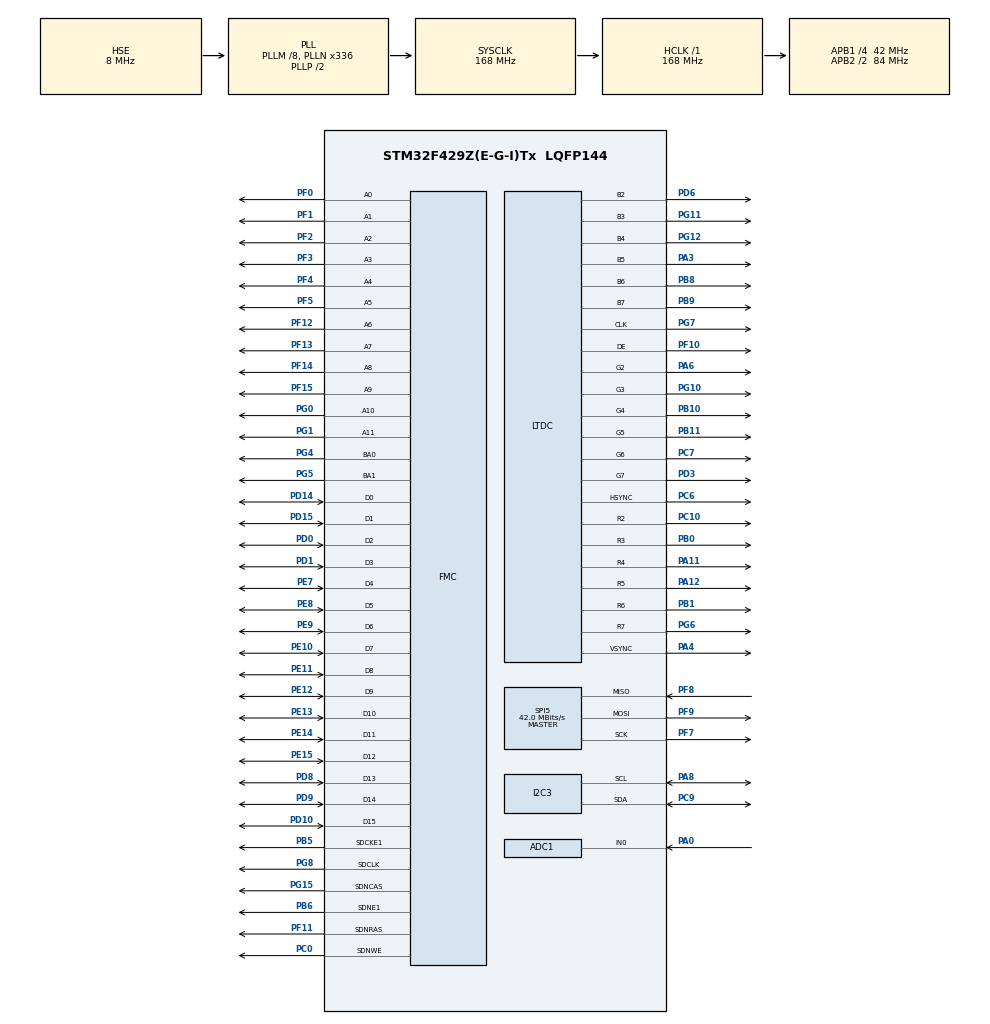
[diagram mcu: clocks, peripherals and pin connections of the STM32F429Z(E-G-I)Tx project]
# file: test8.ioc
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ADC1.Channel-0\#ChannelRegularConversion=ADC_CHANNEL_0
ADC1.Channel-1\#ChannelInjectedConversion=ADC_CHANNEL_0
ADC1.ContinuousConvMode=ENABLE
ADC1.InjNumberOfConversion=1
ADC1.InjectedOffset-1\#ChannelInjectedConversion=0
ADC1.NbrOfConversionFlag=1
ADC1.Rank-0\#ChannelRegularConversion=1
ADC1.Rank-1\#ChannelInjectedConversion=1
ADC1.SamplingTime-0\#ChannelRegularConversion=ADC_SAMPLETIME_3CYCLES
ADC1.SamplingTime-1\#ChannelInjectedConversion=ADC_SAMPLETIME_3CYCLES
ADC1.ScanConvMode=ENABLE
ADC1.master=1
DMA2D.ColorMode=DMA2D_RGB565
LTDC.ActiveH=240
LTDC.ActiveW=320
Mcu.Family=STM32F4
Mcu.Name=STM32F429Z(E-G-I)Tx
Mcu.Package=LQFP144
NVIC.PriorityGroup=NVIC_PRIORITYGROUP_4
PA0/WKUP.Signal=ADCx_IN0
PA11.Mode=RGB666
PA11.Signal=LTDC_R4
PA12.Mode=RGB666
PA12.Signal=LTDC_R5
PA3.Mode=RGB666
PA3.Signal=LTDC_B5
PA4.Mode=RGB666
PA4.Signal=LTDC_VSYNC
PA6.Mode=RGB666
PA6.Signal=LTDC_G2
PA8.Mode=I2C
PA8.Signal=I2C3_SCL
PB0.Mode=RGB666
PB0.Signal=LTDC_R3
PB1.Mode=RGB666
PB1.Signal=LTDC_R6
PB10.Mode=RGB666
PB10.Signal=LTDC_G4
PB11.Mode=RGB666
PB11.Signal=LTDC_G5
PB5.Mode=SdramChipSelect2_1
PB5.Signal=FMC_SDCKE1
PB6.Mode=SdramChipSelect2_1
PB6.Signal=FMC_SDNE1
PB8.Mode=RGB666
PB8.Signal=LTDC_B6
PB9.Mode=RGB666
PB9.Signal=LTDC_B7
PC0.Signal=FMC_SDNWE
PC10.Mode=RGB666
PC10.Signal=LTDC_R2
PC6.Mode=RGB666
PC6.Signal=LTDC_HSYNC
PC7.Mode=RGB666
PC7.Signal=LTDC_G6
PC9.Mode=I2C
PC9.Signal=I2C3_SDA
PD0.Signal=FMC_D2_DA2
PD1.Signal=FMC_D3_DA3
PD10.Signal=FMC_D15_DA15
PD14.Signal=FMC_D0_DA0
PD15.Signal=FMC_D1_DA1
PD3.Mode=RGB666
PD3.Signal=LTDC_G7
PD6.Mode=RGB666
PD6.Signal=LTDC_B2
PD8.Signal=FMC_D13_DA13
PD9.Signal=FMC_D14_DA14
PE10.Signal=FMC_D7_DA7
PE11.Signal=FMC_D8_DA8
PE12.Signal=FMC_D9_DA9
PE13.Signal=FMC_D10_DA10
PE14.Signal=FMC_D11_DA11
PE15.Signal=FMC_D12_DA12
PE7.Signal=FMC_D4_DA4
PE8.Signal=FMC_D5_DA5
PE9.Signal=FMC_D6_DA6
PF0.Signal=FMC_A0
PF1.Signal=FMC_A1
PF10.Mode=RGB666
PF10.Signal=LTDC_DE
PF11.Signal=FMC_SDNRAS
PF12.Signal=FMC_A6
PF13.Signal=FMC_A7
PF14.Signal=FMC_A8
PF15.Signal=FMC_A9
PF2.Signal=FMC_A2
PF3.Signal=FMC_A3
PF4.Signal=FMC_A4
PF5.Signal=FMC_A5
PF7.Mode=Full_Duplex_Master
PF7.Signal=SPI5_SCK
PF8.Mode=Full_Duplex_Master
PF8.Signal=SPI5_MISO
PF9.Mode=Full_Duplex_Master
PF9.Signal=SPI5_MOSI
PG0.Signal=FMC_A10
PG1.Signal=FMC_A11
PG10.Mode=RGB666
PG10.Signal=LTDC_G3
PG11.Mode=RGB666
PG11.Signal=LTDC_B3
PG12.Mode=RGB666
PG12.Signal=LTDC_B4
PG15.Signal=FMC_SDNCAS
PG4.Signal=FMC_A14_BA0
PG5.Signal=FMC_A15_BA1
PG6.Mode=RGB666
PG6.Signal=LTDC_R7
PG7.Mode=RGB666
PG7.Signal=LTDC_CLK
PG8.Signal=FMC_SDCLK
PH0/OSC_IN.Mode=HSE-External-Oscillator
PH0/OSC_IN.Signal=RCC_OSC_IN
PH1/OSC_OUT.Mode=HSE-External-Oscillator
PH1/OSC_OUT.Signal=RCC_OSC_OUT
ProjectManager.TargetToolchain=MDK-ARM V5
RCC.48MHZClocksFreq_Value=42000000
RCC.AHBFreq_Value=168000000
RCC.APB1CLKDivider=RCC_HCLK_DIV4
RCC.APB1Freq_Value=42000000
RCC.APB1TimFreq_Value=84000000
RCC.APB2CLKDivider=RCC_HCLK_DIV2
RCC.APB2Freq_Value=84000000
RCC.APB2TimFreq_Value=168000000
RCC.CortexFreq_Value=168000000
RCC.HCLKFreq_Value=168000000
RCC.HSE_VALUE=8000000
RCC.HSI_VALUE=16000000
RCC.LSE_VALUE=32768
RCC.PLLM=8
RCC.PLLN=336
RCC.PLLQ=8
RCC.PLLSAIN=432
RCC.PLLSourceVirtual=RCC_PLLSOURCE_HSE
RCC.SYSCLKFreq_VALUE=168000000
RCC.SYSCLKSource=RCC_SYSCLKSOURCE_PLLCLK
RCC.VCOOutputFreq_Value=336000000
SH.ADCx_IN0.0=ADC1_IN0,IN0
SH.FMC_A0.0=FMC_A0,12b-sda1
SH.FMC_A1.0=FMC_A1,12b-sda1
SH.FMC_A10.0=FMC_A10,12b-sda1
SH.FMC_A11.0=FMC_A11,12b-sda1
SH.FMC_A14_BA0.0=FMC_BA0,FourSdramBanks1
SH.FMC_A15_BA1.0=FMC_BA1,FourSdramBanks1
SH.FMC_A2.0=FMC_A2,12b-sda1
SH.FMC_A3.0=FMC_A3,12b-sda1
SH.FMC_A4.0=FMC_A4,12b-sda1
SH.FMC_A5.0=FMC_A5,12b-sda1
SH.FMC_A6.0=FMC_A6,12b-sda1
SH.FMC_A7.0=FMC_A7,12b-sda1
SH.FMC_A8.0=FMC_A8,12b-sda1
SH.FMC_A9.0=FMC_A9,12b-sda1
SH.FMC_D0_DA0.0=FMC_D0,sd-16b-d1
SH.FMC_D10_DA10.0=FMC_D10,sd-16b-d1
SH.FMC_D11_DA11.0=FMC_D11,sd-16b-d1
SH.FMC_D12_DA12.0=FMC_D12,sd-16b-d1
SH.FMC_D13_DA13.0=FMC_D13,sd-16b-d1
SH.FMC_D14_DA14.0=FMC_D14,sd-16b-d1
SH.FMC_D15_DA15.0=FMC_D15,sd-16b-d1
SH.FMC_D1_DA1.0=FMC_D1,sd-16b-d1
SH.FMC_D2_DA2.0=FMC_D2,sd-16b-d1
SH.FMC_D3_DA3.0=FMC_D3,sd-16b-d1
SH.FMC_D4_DA4.0=FMC_D4,sd-16b-d1
SH.FMC_D5_DA5.0=FMC_D5,sd-16b-d1
SH.FMC_D6_DA6.0=FMC_D6,sd-16b-d1
SH.FMC_D7_DA7.0=FMC_D7,sd-16b-d1
SH.FMC_D8_DA8.0=FMC_D8,sd-16b-d1
SH.FMC_D9_DA9.0=FMC_D9,sd-16b-d1
SH.FMC_SDCLK.0=FMC_SDCLK,12b-sda1
SH.FMC_SDNCAS.0=FMC_SDNCAS,12b-sda1
SH.FMC_SDNRAS.0=FMC_SDNRAS,12b-sda1
SH.FMC_SDNWE.0=FMC_SDNWE,12b-sda1
SPI5.CalculateBaudRate=42.0 MBits/s
SPI5.Mode=SPI_MODE_MASTER
VP_DMA2D_VS_DMA2D.Mode=DMA2D_Activate
VP_RNG_VS_RNG.Mode=RNG_Activate
board=test2

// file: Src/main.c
/**
  ******************************************************************************
  * File Name          : main.c
  * Description        : Main program body
  ******************************************************************************
  *
  * COPYRIGHT(c) 2015 STMicroelectronics
  *
  * Redistribution and use in source and binary forms, with or without modification,
  * are permitted provided that the following conditions are met:
  *   1. Redistributions of source code must retain the above copyright notice,
  *      this list of conditions and the following disclaimer.
  *   2. Redistributions in binary form must reproduce the above copyright notice,
  *      this list of conditions and the following disclaimer in the documentation
  *      and/or other materials provided with the distribution.
  *   3. Neither the name of STMicroelectronics nor the names of its contributors
  *      may be used to endorse or promote products derived from this software
  *      without specific prior written permission.
  *
  * THIS SOFTWARE IS PROVIDED BY THE COPYRIGHT HOLDERS AND CONTRIBUTORS "AS IS"
  * AND ANY EXPRESS OR IMPLIED WARRANTIES, INCLUDING, BUT NOT LIMITED TO, THE
  * IMPLIED WARRANTIES OF MERCHANTABILITY AND FITNESS FOR A PARTICULAR PURPOSE ARE
  * DISCLAIMED. IN NO EVENT SHALL THE COPYRIGHT HOLDER OR CONTRIBUTORS BE LIABLE
  * FOR ANY DIRECT, INDIRECT, INCIDENTAL, SPECIAL, EXEMPLARY, OR CONSEQUENTIAL
  * DAMAGES (INCLUDING, BUT NOT LIMITED TO, PROCUREMENT OF SUBSTITUTE GOODS OR
  * SERVICES; LOSS OF USE, DATA, OR PROFITS; OR BUSINESS INTERRUPTION) HOWEVER
  * CAUSED AND ON ANY THEORY OF LIABILITY, WHETHER IN CONTRACT, STRICT LIABILITY,
  * OR TORT (INCLUDING NEGLIGENCE OR OTHERWISE) ARISING IN ANY WAY OUT OF THE USE
  * OF THIS SOFTWARE, EVEN IF ADVISED OF THE POSSIBILITY OF SUCH DAMAGE.
  *
  ******************************************************************************
  */
#include "stm32f4xx_hal.h"
#include "stm32f4xx.h"
#include <stdio.h>
#include "stdint.h"
#include "arm_math.h"

/* USER CODE BEGIN Includes */
#include "stm32f429i_discovery_lcd.h"
/* USER CODE END Includes */

#define MAX_VALUE 4095.0
#define SIZE 2048
#define FREQ_FACTOR 58
#define CAP_FACTOR 5 //spadek napiecia na kondensatorze

ADC_HandleTypeDef hadc1;

DMA2D_HandleTypeDef hdma2d;

I2C_HandleTypeDef hi2c3;

LTDC_HandleTypeDef hltdc;

RNG_HandleTypeDef hrng;

SPI_HandleTypeDef hspi5;

SDRAM_HandleTypeDef hsdram1;

/* USER CODE BEGIN PV */
/* Private variables ---------------------------------------------------------*/

/* USER CODE END PV */

void SystemClock_Config(void);
static void MX_GPIO_Init(void);
static void MX_ADC1_Init(void);
static void MX_DMA2D_Init(void);
static void MX_FMC_Init(void);
static void MX_I2C3_Init(void);
static void MX_LTDC_Init(void);
static void MX_RNG_Init(void);
static void MX_SPI5_Init(void);

uint32_t samples[SIZE];

uint32_t scale(uint32_t value) {
	return value/MAX_VALUE*240;
}

uint32_t find_trigger_point(uint32_t *samples) {
	uint32_t middle = MAX_VALUE/2;

	for(int i = 2; i < SIZE; i += 2) {
		if(samples[i] > middle && samples[i-2] < middle) {
			return i;
		}
	}
	return -1;
}

void display_samples(uint32_t *samples) {
	uint32_t trigger_point = find_trigger_point(samples); //to synchronize
	BSP_LCD_Clear(LCD_COLOR_BLACK);
	for(uint32_t i = trigger_point+2; i < SIZE; i += 2) {
		BSP_LCD_DrawPixel(scale(samples[i]),i-trigger_point,LCD_COLOR_WHITE);
	}
}

float32_t INPUT[SIZE];
float32_t Output[SIZE];

void fft();

int main(void)
{

  HAL_Init();

  SystemClock_Config();

  MX_GPIO_Init();
  MX_ADC1_Init();
  MX_DMA2D_Init();
  MX_FMC_Init();
  MX_I2C3_Init();
  MX_LTDC_Init();
  MX_RNG_Init();
  MX_SPI5_Init();

	BSP_LCD_Init();
	BSP_LCD_LayerDefaultInit(LCD_BACKGROUND_LAYER, LCD_FRAME_BUFFER);
	BSP_LCD_LayerDefaultInit(LCD_FOREGROUND_LAYER, LCD_FRAME_BUFFER);
	BSP_LCD_SelectLayer(LCD_FOREGROUND_LAYER);
	BSP_LCD_Clear(LCD_COLOR_BLACK);
	BSP_LCD_DisplayOn();
	uint8_t Button_Value;
	GPIO_InitTypeDef GPIO_InitStruct;
  GPIO_InitStruct.Pin |= GPIO_PIN_0;
  GPIO_InitStruct.Mode = 0x00;
  GPIO_InitStruct.Pull = 0x02;
  HAL_GPIO_Init(GPIOA, &GPIO_InitStruct);
	while (1)
		{

		for(uint16_t i = 0; i < SIZE; i+=2) {
			HAL_ADC_Start(&hadc1);
			HAL_ADC_PollForConversion(&hadc1,1000);
			samples[i] = HAL_ADC_GetValue(&hadc1);
			samples[i+1] = 0;
			HAL_ADC_Stop(&hadc1);
		}

		Button_Value = HAL_GPIO_ReadPin(GPIOA, GPIO_PIN_0);
		if( Button_Value )
		{
			fft();

		}
		else
		{

			display_samples(samples);

		}
	}
}

/**FFT
*/

void fft(){
	uint32_t i;
	arm_cfft_radix4_instance_f32 S;	/* ARM CFFT module */
	float32_t maxValue;				/* Max FFT value is stored here */
	uint32_t maxIndex;				/* Index in Output array where max value is */
	uint32_t height;
	for(i = 0; i < SIZE; i+=2)
	{
		INPUT[i] = ((samples[i]+CAP_FACTOR)/((float32_t) MAX_VALUE/2) - 1);
		INPUT[i+1] = 0;
	}
			/* Initialize the CFFT/CIFFT module, intFlag = 0, doBitReverse = 1 */
		arm_cfft_radix4_init_f32(&S, SIZE/2, 0, 1);
		/* Process the data through the CFFT/CIFFT module */
		arm_cfft_radix4_f32(&S, INPUT);
		/* Process the data through the Complex Magniture Module for calculating the magnitude at each bin */
		arm_cmplx_mag_f32(INPUT, Output, SIZE/2);
		/* Calculates maxValue and returns corresponding value */
		arm_max_f32(Output, SIZE, &maxValue, &maxIndex);
		if(maxIndex>SIZE/4){
			maxIndex=SIZE/2-maxIndex;		//Dla lustrzanych
		}
		BSP_LCD_Clear(LCD_COLOR_WHITE);
		/* Display data on LCD */
		for (i = 0; i < SIZE; i++) {
			/* Draw FFT results */
				height = (uint16_t)(((float32_t)Output[i] / (float32_t)maxValue) * 180);
				BSP_LCD_DrawLine(0, 30+i, height, 30+i);

		}
		char str[16];
		sprintf(str,"%d",(uint32_t)((float32_t)maxIndex*FREQ_FACTOR)); //Model matematyczny
		BSP_LCD_DisplayStringAtLine(1,(uint8_t *) str);
}
/** System Clock Configuration
*/
void SystemClock_Config(void)
{

  RCC_OscInitTypeDef RCC_OscInitStruct;
  RCC_ClkInitTypeDef RCC_ClkInitStruct;
  RCC_PeriphCLKInitTypeDef PeriphClkInitStruct;

  __PWR_CLK_ENABLE();

  __HAL_PWR_VOLTAGESCALING_CONFIG(PWR_REGULATOR_VOLTAGE_SCALE1);

  RCC_OscInitStruct.OscillatorType = RCC_OSCILLATORTYPE_HSE;
  RCC_OscInitStruct.HSEState = RCC_HSE_ON;
  RCC_OscInitStruct.PLL.PLLState = RCC_PLL_ON;
  RCC_OscInitStruct.PLL.PLLSource = RCC_PLLSOURCE_HSE;
  RCC_OscInitStruct.PLL.PLLM = 8;
  RCC_OscInitStruct.PLL.PLLN = 336;
  RCC_OscInitStruct.PLL.PLLP = RCC_PLLP_DIV2;
  RCC_OscInitStruct.PLL.PLLQ = 8;
  HAL_RCC_OscConfig(&RCC_OscInitStruct);

  RCC_ClkInitStruct.ClockType = RCC_CLOCKTYPE_SYSCLK|RCC_CLOCKTYPE_PCLK1
                              |RCC_CLOCKTYPE_PCLK2;
  RCC_ClkInitStruct.SYSCLKSource = RCC_SYSCLKSOURCE_PLLCLK;
  RCC_ClkInitStruct.AHBCLKDivider = RCC_SYSCLK_DIV1;
  RCC_ClkInitStruct.APB1CLKDivider = RCC_HCLK_DIV4;
  RCC_ClkInitStruct.APB2CLKDivider = RCC_HCLK_DIV2;
  HAL_RCC_ClockConfig(&RCC_ClkInitStruct, FLASH_LATENCY_5);

  PeriphClkInitStruct.PeriphClockSelection = RCC_PERIPHCLK_LTDC;
  PeriphClkInitStruct.PLLSAI.PLLSAIN = 432;
  PeriphClkInitStruct.PLLSAI.PLLSAIR = 2;
  PeriphClkInitStruct.PLLSAIDivR = RCC_PLLSAIDIVR_2;
  HAL_RCCEx_PeriphCLKConfig(&PeriphClkInitStruct);

  HAL_SYSTICK_Config(HAL_RCC_GetHCLKFreq()/1000);

  HAL_SYSTICK_CLKSourceConfig(SYSTICK_CLKSOURCE_HCLK);

}

/* ADC1 init function */
void MX_ADC1_Init(void)
{

  ADC_ChannelConfTypeDef sConfig;
  ADC_InjectionConfTypeDef sConfigInjected;

    /**Configure the global features of the ADC (Clock, Resolution, Data Alignment and number of conversion)
    */
  hadc1.Instance = ADC1;
  hadc1.Init.ClockPrescaler = ADC_CLOCKPRESCALER_PCLK_DIV4;
  hadc1.Init.Resolution = ADC_RESOLUTION12b;
  hadc1.Init.ScanConvMode = ENABLE;
  hadc1.Init.ContinuousConvMode = ENABLE;
  hadc1.Init.DiscontinuousConvMode = DISABLE;
  hadc1.Init.ExternalTrigConvEdge = ADC_EXTERNALTRIGCONVEDGE_NONE;
  hadc1.Init.DataAlign = ADC_DATAALIGN_RIGHT;
  hadc1.Init.NbrOfConversion = 1;
  hadc1.Init.DMAContinuousRequests = DISABLE;
  hadc1.Init.EOCSelection = EOC_SINGLE_CONV;
  HAL_ADC_Init(&hadc1);

    /**Configure for the selected ADC regular channel its corresponding rank in the sequencer and its sample time.
    */
  sConfig.Channel = ADC_CHANNEL_5;
  sConfig.Rank = 1;
  sConfig.SamplingTime = ADC_SAMPLETIME_3CYCLES;
  HAL_ADC_ConfigChannel(&hadc1, &sConfig);

    /**Configures for the selected ADC injected channel its corresponding rank in the sequencer and its sample time
    */
  sConfigInjected.InjectedChannel = ADC_CHANNEL_5;
  sConfigInjected.InjectedRank = 1;
  sConfigInjected.InjectedNbrOfConversion = 1;
  sConfigInjected.InjectedSamplingTime = ADC_SAMPLETIME_3CYCLES;
  sConfigInjected.ExternalTrigInjecConvEdge = ADC_EXTERNALTRIGINJECCONVEDGE_NONE;
  sConfigInjected.AutoInjectedConv = DISABLE;
  sConfigInjected.InjectedDiscontinuousConvMode = DISABLE;
  sConfigInjected.InjectedOffset = 0;
  HAL_ADCEx_InjectedConfigChannel(&hadc1, &sConfigInjected);

}

/* DMA2D init function */
void MX_DMA2D_Init(void)
{

  hdma2d.Instance = DMA2D;
  hdma2d.Init.Mode = DMA2D_M2M;
  hdma2d.Init.ColorMode = DMA2D_RGB565;
  hdma2d.Init.OutputOffset = 0;
  hdma2d.LayerCfg[1].InputOffset = 0;
  hdma2d.LayerCfg[1].InputColorMode = CM_RGB565;
  hdma2d.LayerCfg[1].AlphaMode = DMA2D_NO_MODIF_ALPHA;
  hdma2d.LayerCfg[1].InputAlpha = 0;
  HAL_DMA2D_Init(&hdma2d);

  HAL_DMA2D_ConfigLayer(&hdma2d, 1);

}

/* I2C3 init function */
void MX_I2C3_Init(void)
{

  hi2c3.Instance = I2C3;
  hi2c3.Init.ClockSpeed = 100000;
  hi2c3.Init.DutyCycle = I2C_DUTYCYCLE_2;
  hi2c3.Init.OwnAddress1 = 0;
  hi2c3.Init.AddressingMode = I2C_ADDRESSINGMODE_7BIT;
  hi2c3.Init.DualAddressMode = I2C_DUALADDRESS_DISABLED;
  hi2c3.Init.OwnAddress2 = 0;
  hi2c3.Init.GeneralCallMode = I2C_GENERALCALL_DISABLED;
  hi2c3.Init.NoStretchMode = I2C_NOSTRETCH_DISABLED;
  HAL_I2C_Init(&hi2c3);

}

/* LTDC init function */
void MX_LTDC_Init(void)
{

  LTDC_LayerCfgTypeDef pLayerCfg;
  LTDC_LayerCfgTypeDef pLayerCfg1;

  hltdc.Instance = LTDC;
  hltdc.Init.HSPolarity = LTDC_HSPOLARITY_AL;
  hltdc.Init.VSPolarity = LTDC_VSPOLARITY_AL;
  hltdc.Init.DEPolarity = LTDC_DEPOLARITY_AL;
  hltdc.Init.PCPolarity = LTDC_PCPOLARITY_IPC;
  hltdc.Init.HorizontalSync = 7;
  hltdc.Init.VerticalSync = 3;
  hltdc.Init.AccumulatedHBP = 14;
  hltdc.Init.AccumulatedVBP = 5;
  hltdc.Init.AccumulatedActiveW = 334;
  hltdc.Init.AccumulatedActiveH = 245;
  hltdc.Init.TotalWidth = 340;
  hltdc.Init.TotalHeigh = 247;
  hltdc.Init.Backcolor.Blue = 0;
  hltdc.Init.Backcolor.Green = 0;
  hltdc.Init.Backcolor.Red = 0;
  HAL_LTDC_Init(&hltdc);

  pLayerCfg.WindowX0 = 0;
  pLayerCfg.WindowX1 = 0;
  pLayerCfg.WindowY0 = 0;
  pLayerCfg.WindowY1 = 0;
  pLayerCfg.PixelFormat = LTDC_PIXEL_FORMAT_ARGB8888;
  pLayerCfg.Alpha = 0;
  pLayerCfg.Alpha0 = 0;
  pLayerCfg.BlendingFactor1 = LTDC_BLENDING_FACTOR1_CA;
  pLayerCfg.BlendingFactor2 = LTDC_BLENDING_FACTOR2_CA;
  pLayerCfg.FBStartAdress = 0;
  pLayerCfg.ImageWidth = 0;
  pLayerCfg.ImageHeight = 0;
  pLayerCfg.Backcolor.Blue = 0;
  pLayerCfg.Backcolor.Green = 0;
  pLayerCfg.Backcolor.Red = 0;
  HAL_LTDC_ConfigLayer(&hltdc, &pLayerCfg, 0);

  pLayerCfg1.WindowX0 = 0;
  pLayerCfg1.WindowX1 = 0;
  pLayerCfg1.WindowY0 = 0;
  pLayerCfg1.WindowY1 = 0;
  pLayerCfg1.PixelFormat = LTDC_PIXEL_FORMAT_ARGB8888;
  pLayerCfg1.Alpha = 0;
  pLayerCfg1.Alpha0 = 0;
  pLayerCfg1.BlendingFactor1 = LTDC_BLENDING_FACTOR1_CA;
  pLayerCfg1.BlendingFactor2 = LTDC_BLENDING_FACTOR2_CA;
  pLayerCfg1.FBStartAdress = 0;
  pLayerCfg1.ImageWidth = 0;
  pLayerCfg1.ImageHeight = 0;
  pLayerCfg1.Backcolor.Blue = 0;
  pLayerCfg1.Backcolor.Green = 0;
  pLayerCfg1.Backcolor.Red = 0;
  HAL_LTDC_ConfigLayer(&hltdc, &pLayerCfg1, 1);

}

/* RNG init function */
void MX_RNG_Init(void)
{

  hrng.Instance = RNG;
  HAL_RNG_Init(&hrng);

}

/* SPI5 init function */
void MX_SPI5_Init(void)
{

  hspi5.Instance = SPI5;
  hspi5.Init.Mode = SPI_MODE_MASTER;
  hspi5.Init.Direction = SPI_DIRECTION_2LINES;
  hspi5.Init.DataSize = SPI_DATASIZE_8BIT;
  hspi5.Init.CLKPolarity = SPI_POLARITY_LOW;
  hspi5.Init.CLKPhase = SPI_PHASE_1EDGE;
  hspi5.Init.NSS = SPI_NSS_SOFT;
  hspi5.Init.BaudRatePrescaler = SPI_BAUDRATEPRESCALER_2;
  hspi5.Init.FirstBit = SPI_FIRSTBIT_MSB;
  hspi5.Init.TIMode = SPI_TIMODE_DISABLED;
  hspi5.Init.CRCCalculation = SPI_CRCCALCULATION_DISABLED;
  hspi5.Init.CRCPolynomial = 10;
  HAL_SPI_Init(&hspi5);

}
/* FMC initialization function */
void MX_FMC_Init(void)
{
  FMC_SDRAM_TimingTypeDef SdramTiming;

  /** Perform the SDRAM1 memory initialization sequence
  */
  hsdram1.Instance = FMC_SDRAM_DEVICE;
  /* hsdram1.Init */
  hsdram1.Init.SDBank = FMC_SDRAM_BANK2;
  hsdram1.Init.ColumnBitsNumber = FMC_SDRAM_COLUMN_BITS_NUM_8;
  hsdram1.Init.RowBitsNumber = FMC_SDRAM_ROW_BITS_NUM_11;
  hsdram1.Init.MemoryDataWidth = FMC_SDRAM_MEM_BUS_WIDTH_16;
  hsdram1.Init.InternalBankNumber = FMC_SDRAM_INTERN_BANKS_NUM_4;
  hsdram1.Init.CASLatency = FMC_SDRAM_CAS_LATENCY_1;
  hsdram1.Init.WriteProtection = FMC_SDRAM_WRITE_PROTECTION_DISABLE;
  hsdram1.Init.SDClockPeriod = FMC_SDRAM_CLOCK_DISABLE;
  hsdram1.Init.ReadBurst = FMC_SDRAM_RBURST_DISABLE;
  hsdram1.Init.ReadPipeDelay = FMC_SDRAM_RPIPE_DELAY_0;
  /* SdramTiming */
  SdramTiming.LoadToActiveDelay = 16;
  SdramTiming.ExitSelfRefreshDelay = 16;
  SdramTiming.SelfRefreshTime = 16;
  SdramTiming.RowCycleDelay = 16;
  SdramTiming.WriteRecoveryTime = 16;
  SdramTiming.RPDelay = 16;
  SdramTiming.RCDDelay = 16;

  HAL_SDRAM_Init(&hsdram1, &SdramTiming);

}

void MX_GPIO_Init(void)
{

  __GPIOF_CLK_ENABLE();
  __GPIOH_CLK_ENABLE();
  __GPIOC_CLK_ENABLE();
  __GPIOA_CLK_ENABLE();
  __GPIOB_CLK_ENABLE();
  __GPIOG_CLK_ENABLE();
  __GPIOE_CLK_ENABLE();
  __GPIOD_CLK_ENABLE();

}
